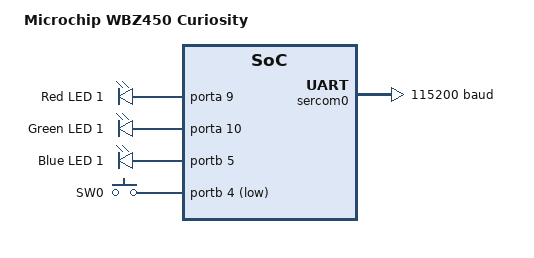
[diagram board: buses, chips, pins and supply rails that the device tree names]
/*
 * Copyright (c) 2025 Microchip Technology Inc.
 *
 * SPDX-License-Identifier: Apache-2.0
 */

/dts-v1/;
#include <microchip/pic32c/pic32cx_bz/bz2x/bz24/pic32cx1012bz24032.dtsi>
#include "wbz450_curiosity-pinctrl.dtsi"
#include <zephyr/dt-bindings/input/input-event-codes.h>

/ {
	model = "Microchip WBZ450 Curiosity";
	compatible = "microchip,wbz450-curiosity";

	chosen {
		zephyr,console = &sercom0;
		zephyr,shell-uart = &sercom0;
		zephyr,sram = &sram0;
	};

	leds {
		compatible = "gpio-leds";
		led0: led_0 {
			gpios = <&porta 9 GPIO_ACTIVE_HIGH>;
			label = "Red LED 1";
		};
		led1: led_1 {
			gpios = <&porta 10 GPIO_ACTIVE_HIGH>;
			label = "Green LED 1";
		};
		led2: led_2 {
			gpios = <&portb 5 GPIO_ACTIVE_HIGH>;
			label = "Blue LED 1";
		};
	};

	buttons {
		compatible = "gpio-keys";
		button0: button_0 {
			gpios = <&portb 4 (GPIO_PULL_UP | GPIO_ACTIVE_LOW)>;
			label = "SW0";
			zephyr,code = <INPUT_KEY_0>;
		};
	};
	/* These aliases are provided for compatibility with samples */
	aliases {
		led0 = &led0;
		led1 = &led1;
		led2 = &led2;
		sw0 = &button0;
	};
};

&cpu0 {
	clock-frequency = <64000000>;
};


&sercom0 {
	status = "okay";
	compatible = "microchip,sercom-g1-uart";
		rxpo = <1>;
		txpo = <0>;
	current-speed = <115200>;
	pinctrl-0 = <&sercom0_uart_default>;
	pinctrl-names = "default";

	dmas = <&dmac 0 4>, <&dmac 1 5>;
	dma-names = "rx", "tx";
};

&porta {
	status = "okay";
};

&portb {
	status = "okay";
};
